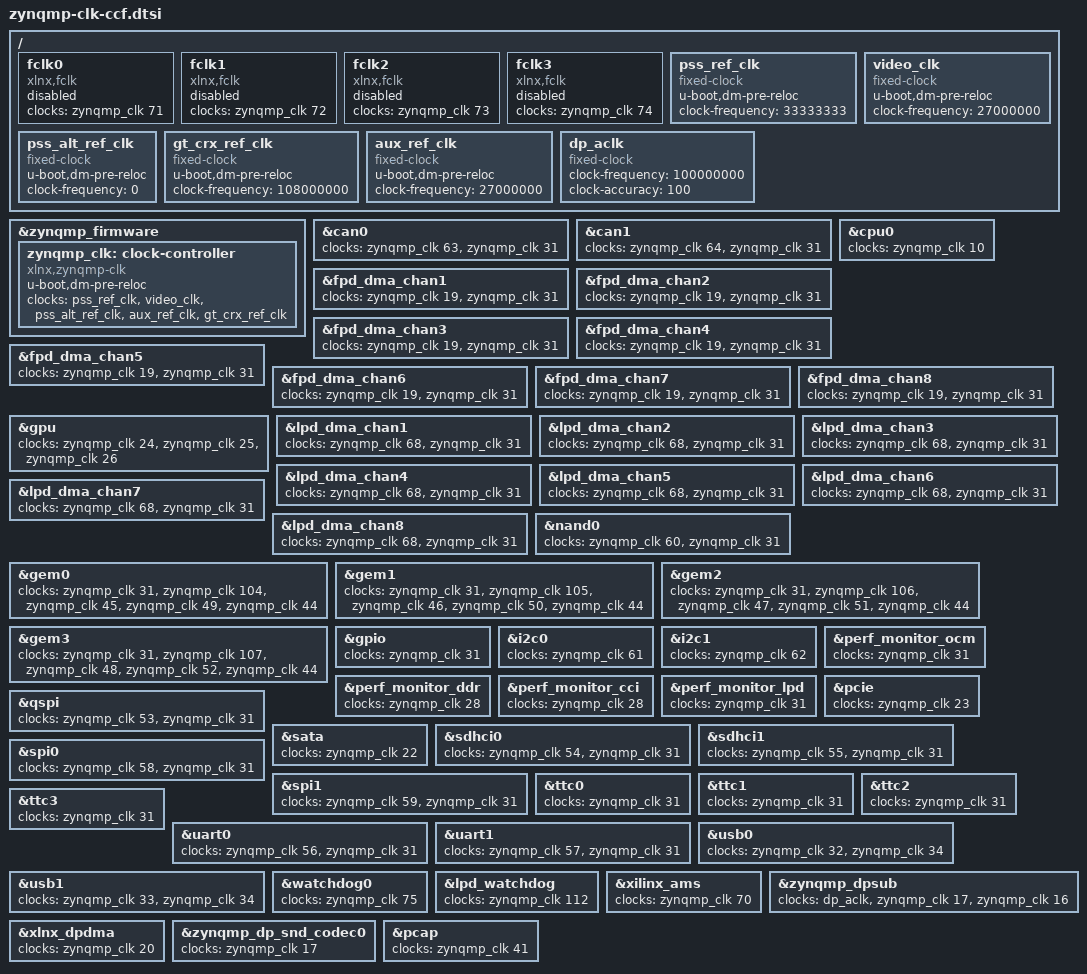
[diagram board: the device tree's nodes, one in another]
// SPDX-License-Identifier: GPL-2.0+
/*
 * Clock specification for Xilinx ZynqMP
 *
 * (C) Copyright 2017, Xilinx, Inc.
 *
 * Michal Simek <michal.simek@xilinx.com>
 */

/ {
	fclk0: fclk0 {
		status = "disabled";
		compatible = "xlnx,fclk";
		clocks = <&zynqmp_clk 71>;
	};

	fclk1: fclk1 {
		status = "disabled";
		compatible = "xlnx,fclk";
		clocks = <&zynqmp_clk 72>;
	};

	fclk2: fclk2 {
		status = "disabled";
		compatible = "xlnx,fclk";
		clocks = <&zynqmp_clk 73>;
	};

	fclk3: fclk3 {
		status = "disabled";
		compatible = "xlnx,fclk";
		clocks = <&zynqmp_clk 74>;
	};

	pss_ref_clk: pss_ref_clk {
		u-boot,dm-pre-reloc;
		compatible = "fixed-clock";
		#clock-cells = <0>;
		clock-frequency = <33333333>;
	};

	video_clk: video_clk {
		u-boot,dm-pre-reloc;
		compatible = "fixed-clock";
		#clock-cells = <0>;
		clock-frequency = <27000000>;
	};

	pss_alt_ref_clk: pss_alt_ref_clk {
		u-boot,dm-pre-reloc;
		compatible = "fixed-clock";
		#clock-cells = <0>;
		clock-frequency = <0>;
	};

	gt_crx_ref_clk: gt_crx_ref_clk {
		u-boot,dm-pre-reloc;
		compatible = "fixed-clock";
		#clock-cells = <0>;
		clock-frequency = <108000000>;
	};

	aux_ref_clk: aux_ref_clk {
		u-boot,dm-pre-reloc;
		compatible = "fixed-clock";
		#clock-cells = <0>;
		clock-frequency = <27000000>;
	};

	dp_aclk: dp_aclk {
		compatible = "fixed-clock";
		#clock-cells = <0>;
		clock-frequency = <100000000>;
		clock-accuracy = <100>;
	};
};

&zynqmp_firmware {
	zynqmp_clk: clock-controller {
		u-boot,dm-pre-reloc;
		#clock-cells = <1>;
		compatible = "xlnx,zynqmp-clk";
		clocks = <&pss_ref_clk>, <&video_clk>, <&pss_alt_ref_clk>,
			 <&aux_ref_clk>, <&gt_crx_ref_clk>;
		clock-names = "pss_ref_clk", "video_clk", "pss_alt_ref_clk",
			      "aux_ref_clk", "gt_crx_ref_clk";
	};
};

&can0 {
	clocks = <&zynqmp_clk 63>, <&zynqmp_clk 31>;
};

&can1 {
	clocks = <&zynqmp_clk 64>, <&zynqmp_clk 31>;
};

&cpu0 {
	clocks = <&zynqmp_clk 10>;
};

&fpd_dma_chan1 {
	clocks = <&zynqmp_clk 19>, <&zynqmp_clk 31>;
};

&fpd_dma_chan2 {
	clocks = <&zynqmp_clk 19>, <&zynqmp_clk 31>;
};

&fpd_dma_chan3 {
	clocks = <&zynqmp_clk 19>, <&zynqmp_clk 31>;
};

&fpd_dma_chan4 {
	clocks = <&zynqmp_clk 19>, <&zynqmp_clk 31>;
};

&fpd_dma_chan5 {
	clocks = <&zynqmp_clk 19>, <&zynqmp_clk 31>;
};

&fpd_dma_chan6 {
	clocks = <&zynqmp_clk 19>, <&zynqmp_clk 31>;
};

&fpd_dma_chan7 {
	clocks = <&zynqmp_clk 19>, <&zynqmp_clk 31>;
};

&fpd_dma_chan8 {
	clocks = <&zynqmp_clk 19>, <&zynqmp_clk 31>;
};

&gpu {
	clocks = <&zynqmp_clk 24>, <&zynqmp_clk 25>, <&zynqmp_clk 26>;
};

&lpd_dma_chan1 {
	clocks = <&zynqmp_clk 68>, <&zynqmp_clk 31>;
};

&lpd_dma_chan2 {
	clocks = <&zynqmp_clk 68>, <&zynqmp_clk 31>;
};

&lpd_dma_chan3 {
	clocks = <&zynqmp_clk 68>, <&zynqmp_clk 31>;
};

&lpd_dma_chan4 {
	clocks = <&zynqmp_clk 68>, <&zynqmp_clk 31>;
};

&lpd_dma_chan5 {
	clocks = <&zynqmp_clk 68>, <&zynqmp_clk 31>;
};

&lpd_dma_chan6 {
	clocks = <&zynqmp_clk 68>, <&zynqmp_clk 31>;
};

&lpd_dma_chan7 {
	clocks = <&zynqmp_clk 68>, <&zynqmp_clk 31>;
};

&lpd_dma_chan8 {
	clocks = <&zynqmp_clk 68>, <&zynqmp_clk 31>;
};

&nand0 {
	clocks = <&zynqmp_clk 60>, <&zynqmp_clk 31>;
};

&gem0 {
	clocks = <&zynqmp_clk 31>, <&zynqmp_clk 104>, <&zynqmp_clk 45>,
		 <&zynqmp_clk 49>, <&zynqmp_clk 44>;
	clock-names = "pclk", "hclk", "tx_clk", "rx_clk", "tsu_clk";
};

&gem1 {
	clocks = <&zynqmp_clk 31>, <&zynqmp_clk 105>, <&zynqmp_clk 46>,
		 <&zynqmp_clk 50>, <&zynqmp_clk 44>;
	clock-names = "pclk", "hclk", "tx_clk", "rx_clk", "tsu_clk";
};

&gem2 {
	clocks = <&zynqmp_clk 31>, <&zynqmp_clk 106>, <&zynqmp_clk 47>,
		 <&zynqmp_clk 51>, <&zynqmp_clk 44>;
	clock-names = "pclk", "hclk", "tx_clk", "rx_clk", "tsu_clk";
};

&gem3 {
	clocks = <&zynqmp_clk 31>, <&zynqmp_clk 107>, <&zynqmp_clk 48>,
		 <&zynqmp_clk 52>, <&zynqmp_clk 44>;
	clock-names = "pclk", "hclk", "tx_clk", "rx_clk", "tsu_clk";
};

&gpio {
	clocks = <&zynqmp_clk 31>;
};

&i2c0 {
	clocks = <&zynqmp_clk 61>;
};

&i2c1 {
	clocks = <&zynqmp_clk 62>;
};

&perf_monitor_ocm {
	clocks = <&zynqmp_clk 31>;
};

&perf_monitor_ddr {
	clocks = <&zynqmp_clk 28>;
};

&perf_monitor_cci {
	clocks = <&zynqmp_clk 28>;
};

&perf_monitor_lpd {
	clocks = <&zynqmp_clk 31>;
};

&pcie {
	clocks = <&zynqmp_clk 23>;
};

&qspi {
	clocks = <&zynqmp_clk 53>, <&zynqmp_clk 31>;
};

&sata {
	clocks = <&zynqmp_clk 22>;
};

&sdhci0 {
	clocks = <&zynqmp_clk 54>, <&zynqmp_clk 31>;
};

&sdhci1 {
	clocks = <&zynqmp_clk 55>, <&zynqmp_clk 31>;
};

&spi0 {
	clocks = <&zynqmp_clk 58>, <&zynqmp_clk 31>;
};

&spi1 {
	clocks = <&zynqmp_clk 59>, <&zynqmp_clk 31>;
};

&ttc0 {
	clocks = <&zynqmp_clk 31>;
};

&ttc1 {
	clocks = <&zynqmp_clk 31>;
};

&ttc2 {
	clocks = <&zynqmp_clk 31>;
};

&ttc3 {
	clocks = <&zynqmp_clk 31>;
};

&uart0 {
	clocks = <&zynqmp_clk 56>, <&zynqmp_clk 31>;
};

&uart1 {
	clocks = <&zynqmp_clk 57>, <&zynqmp_clk 31>;
};

&usb0 {
	clocks = <&zynqmp_clk 32>, <&zynqmp_clk 34>;
};

&usb1 {
	clocks = <&zynqmp_clk 33>, <&zynqmp_clk 34>;
};

&watchdog0 {
	clocks = <&zynqmp_clk 75>;
};

&lpd_watchdog {
	clocks = <&zynqmp_clk 112>;
};

&xilinx_ams {
	clocks = <&zynqmp_clk 70>;
};

&zynqmp_dpsub {
	clocks = <&dp_aclk>, <&zynqmp_clk 17>, <&zynqmp_clk 16>;
};

&xlnx_dpdma {
	clocks = <&zynqmp_clk 20>;
};

&zynqmp_dp_snd_codec0 {
	clocks = <&zynqmp_clk 17>;
};

&pcap {
	clocks = <&zynqmp_clk 41>;
};
